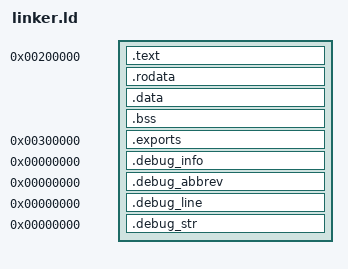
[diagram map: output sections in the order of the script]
ENTRY(_start)

SECTIONS
{
    . = 2M;
    .text BLOCK(4K) : ALIGN(4K)
    {
        *(.multiboot)
        *(.text)
    }

    .rodata BLOCK(4K) : ALIGN(4K)
    {
        *(.rodata)
    }

    .data BLOCK(4K) : ALIGN(4K)
    {
        *(.data)
    }

    .bss BLOCK(4K) : ALIGN(4K)
    {
        *(COMMON)
        *(.bss)
    }

    .exports 0x300000 : ALIGN(4K)
    {
        KEEP(*(.exports))
    }

    .debug_info 0 : { *(.debug_info) }
    .debug_abbrev 0 : { *(.debug_abbrev) }
    .debug_line 0 : { *(.debug_line) }
    .debug_str 0 : { *(.debug_str) }
}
